# ATA5272 device description
Architecture: AVR8; Family: megaAVR
Registers are 8-bit, access not given, no defined reset value unless marked. A register's access mark holds for its fields unless they carry their own. Offsets are from the block's base; [hi:lo] are bit positions; {n}, {i} and the like mark numbered series; 'fields as' and 'values as' point back to an identical list.

## WDT — Watchdog Timer
Instances: WDT 0x00
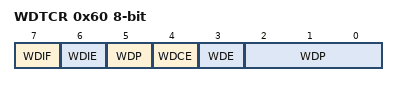
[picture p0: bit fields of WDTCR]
0x60 WDTCR — Watchdog Timer Control Register
  [7] WDIF — Watchdog Timeout Interrupt Flag
  [6] WDIE — Watchdog Timeout Interrupt Enable
  [4] WDCE — Watchdog Change Enable
  [3] WDE — Watch Dog Enable
  [5,2:0] WDP — Watchdog Timer Prescaler Bits
    0=Oscillator Cycles 2K; 1=Oscillator Cycles 4K; 2=Oscillator Cycles 8K; 3=Oscillator Cycles 16K; 4=Oscillator Cycles 32K; 5=Oscillator Cycles 64K; 6=Oscillator Cycles 128K; 7=Oscillator Cycles 256K; 8=Oscillator Cycles 512K; 9=Oscillator Cycles 1024K

## EEPROM
Instances: EEPROM 0x00
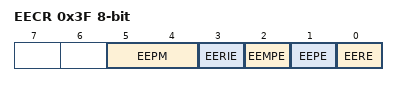
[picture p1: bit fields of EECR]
0x3F EECR — EEPROM Control Register
  [5:4] EEPM — EEPROM Programming Mode Bits
    0=Erase and Write in one operation; 1=Erase Only; 2=Write Only
  [3] EERIE — EEPROM Ready Interrupt Enable
  [2] EEMPE — EEPROM Master Write Enable
  [1] EEPE — EEPROM Write Enable
  [0] EERE — EEPROM Read Enable
0x40 EEDR — EEPROM Data Register
0x41 EEAR 16-bit bits used 8:0 — EEPROM Address Register Bytes

## SPI
Instances: SPI 0x00
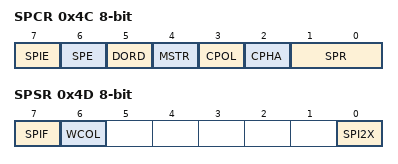
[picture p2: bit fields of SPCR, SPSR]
0x4C SPCR — SPI Control Register
  [7] SPIE — SPI Interrupt Enable
  [6] SPE — SPI Enable
  [5] DORD — Data Order
  [4] MSTR — Master/Slave Select
  [3] CPOL — Clock polarity
  [2] CPHA — Clock Phase
  [1:0] SPR — SPI Clock Rate Selects
    0=fosc/4; 1=fosc/16; 2=fosc/64; 3=fosc/128; 4=fosc/2; 5=fosc/8; 6=fosc/32; 7=fosc/64
0x4D SPSR — SPI Status Register
  [7] SPIF — SPI Interrupt Flag
  [6] WCOL — Write Collision Flag
  [0] SPI2X — Double SPI Speed Bit
0x4E SPDR — SPI Data Register

## AD_CONVERTER
Instances: AD_CONVERTER 0x00
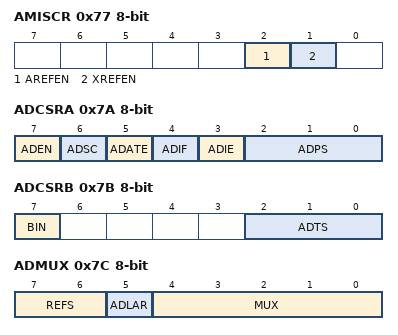
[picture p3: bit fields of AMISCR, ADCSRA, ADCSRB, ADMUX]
0x77 AMISCR — Analog Miscellaneous Control Register (Shared with CURRENT_SOURCE IO_MODULE)
  [2] AREFEN — External Voltage Reference Input Enable
  [1] XREFEN — Internal Voltage Reference Output Enable
0x78 ADC 16-bit — ADC Data Register Bytes
0x7A ADCSRA — The ADC Control and Status register A
  [7] ADEN — ADC Enable
  [6] ADSC — ADC Start Conversion
  [5] ADATE — ADC Auto Trigger Enable
  [4] ADIF — ADC Interrupt Flag
  [3] ADIE — ADC Interrupt Enable
  [2:0] ADPS — ADC Prescaler Select Bits
    0=2; 1=2; 2=4; 3=8; 4=16; 5=32; 6=64; 7=128
0x7B ADCSRB — The ADC Control and Status register B (Shared with ANALOG_COMPARATOR IO_MODULE)
  [7] BIN — Bipolar Input Mode
  [2:0] ADTS — ADC Auto Trigger Source bits
    0=Free Running mode; 1=Analog Comparator; 2=External Interrupt Request 0; 3=Timer/Counter1 Compare Match A; 4=Timer/Counter1 Overflow; 5=Timer/Counter1 Compare Match B; 6=Timer/Counter1 Capture Event; 7=Watchdog Interrupt Request
0x7C ADMUX — The ADC multiplexer Selection Register
  [7:6] REFS — Reference Selection Bits
    0=If AREFEN==0 then Internal AVCC as Voltage Reference. If AREFEN==1 then AREF pin as Voltage Reference.; 1=If AREFEN==0 then Internal 1.1V as Voltage Reference without external capacitor. If AREFEN==1 then Internal 1.1V as Voltage Reference with external capacitor at AREF pin.; 2=If AREFEN==0 then Internal AVCC as Voltage Reference. If AREFEN==1 then AREF pin as Voltage Reference.; 3=If AREFEN==0 then Internal 2.56V as Voltage Reference without external capacitor. If AREFEN==1 then Internal 2.56V as Voltage Reference with external capacitor at AREF pin.
  [5] ADLAR — Left Adjust Result
  [4:0] MUX — Analog Channel and Gain Selection Bits
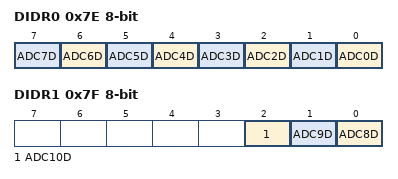
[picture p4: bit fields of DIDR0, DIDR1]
0x7E DIDR0 — Digital Input Disable Register 0
  [n] ADC{n}D (n=0..7)
0x7F DIDR1 — Digital Input Disable Register 1
  [2] ADC10D, [1] ADC9D, [0] ADC8D

## CURRENT_SOURCE
Instances: CURRENT_SOURCE 0x00
0x77 AMISCR — Analog Miscellaneous Control Register (Shared with AD_CONVERTER IO_MODULE)
  [0] ISRCEN — Current Source Enable

## ANALOG_COMPARATOR
Instances: ANALOG_COMPARATOR 0x00
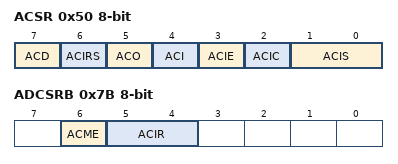
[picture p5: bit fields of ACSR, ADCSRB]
0x50 ACSR — Analog Comparator Control And Status Register
  [7] ACD — Analog Comparator Disable
  [6] ACIRS — Analog Comparator Internal Reference Select
  [5] ACO — Analog Compare Output
  [4] ACI — Analog Comparator Interrupt Flag
  [3] ACIE — Analog Comparator Interrupt Enable
  [2] ACIC — Analog Comparator Input Capture Enable
  [1:0] ACIS — Analog Comparator Interrupt Mode Select bits
    0=Interrupt on Toggle; 2=Interrupt on Falling Edge; 3=Interrupt on Rising Edge
0x7B ADCSRB — Analog Comparator & ADC Control and Status Register B (Shared with AD_CONVERTER IO_MODULE)
  [6] ACME — Analog Comparator Multiplexer Enable
  [5:4] ACIR — Analog Comparator Internal Voltage Reference Select Bits

## EXTERNAL_INTERRUPT
Instances: EXTERNAL_INTERRUPT 0x00
0x3B PCIFR — Pin Change Interrupt Flag Register
  [1:0] PCIF — Pin Change Interrupt Flags
0x3C EIFR — External Interrupt Flag Register
  [1:0] INTF — External Interrupt Flags
0x3D EIMSK — External Interrupt Mask Register
  [1:0] INT — External Interrupt Request 1 Enable
0x68 PCICR — Pin Change Interrupt Control Register
  [1:0] PCIE — Pin Change Interrupt Enable on any PCINT14..8 pin
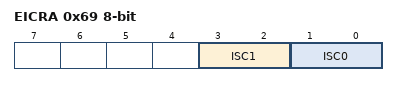
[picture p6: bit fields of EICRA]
0x69 EICRA — External Interrupt Control Register
  [3:2] ISC1 — External Interrupt Sense Control 1 Bits
    0=Low Level of INTX; 1=Any Logical Change in INTX; 2=Falling Edge of INTX; 3=Rising Edge of INTX
  [1:0] ISC0 — External Interrupt Sense Control 0 Bits
    values as ISC1
0x6B PCMSK0 — Pin Change Mask Register 0
  [7:0] PCINT — Pin Change Enable Masks
0x6C PCMSK1 — Pin Change Mask Register 1
  [7:0] PCINT (bit 8 of the value upward) — Pin Change Enable Masks

## BOOT_LOAD
Instances: BOOT_LOAD 0x00
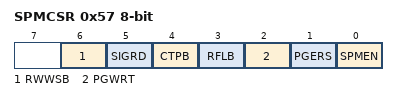
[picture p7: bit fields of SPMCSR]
0x57 SPMCSR — Store Program Memory Control Register
  [6] RWWSB — Read While Write Section Busy
  [5] SIGRD — Signature Row Read
  [4] CTPB — Clear Temporary Page Buffer
  [3] RFLB — Read Fuse and Lock Bits
  [2] PGWRT — Page Write
  [1] PGERS — Page Erase
  [0] SPMEN — Store Program Memory Enable

## CPU
Instances: CPU 0x00
Parameters: CORE_VERSION=V2, NEW_INSTRUCTIONS=lpm rd,z+
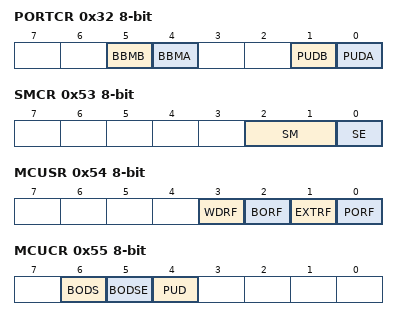
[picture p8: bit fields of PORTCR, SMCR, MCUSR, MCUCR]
0x32 PORTCR — Port Control Register
  [5] BBMB, [4] BBMA, [1] PUDB, [0] PUDA
0x3E GPIOR0 — General purpose register 0
0x4A GPIOR1 — General Purpose register 1
0x4B GPIOR2 — General Purpose IO register 2
0x51 DWDR — debugWire communication register
0x53 SMCR — Sleep Mode Control Register
  [2:1] SM — Sleep Mode Select Bits
    0=IDLE; 1=ADC (ADC Noise Reduction (If Available)); 2=PDOWN (Power Down); 3=PSAVE (Power Save)
  [0] SE — Sleep Enable
0x54 MCUSR — MCU Status register
  [3] WDRF — Watchdog Reset Flag
  [2] BORF — Brown-out Reset Flag
  [1] EXTRF — External Reset Flag
  [0] PORF — Power-On Reset Flag
0x55 MCUCR — MCU Control Register
  [6] BODS — BOD Sleep
  [5] BODSE — BOD Sleep Enable
  [4] PUD — Pull-up Disable
0x5D SP 16-bit bits used 10:0 — Stack Pointer Bytes
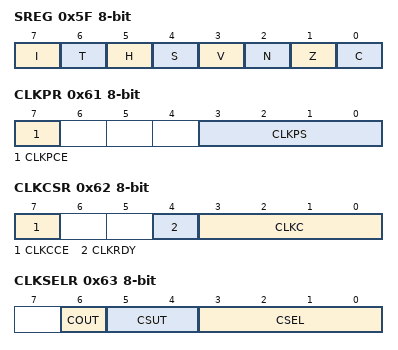
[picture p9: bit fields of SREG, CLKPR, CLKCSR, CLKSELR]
0x5F SREG — Status Register
  [7] I — Global Interrupt Enable
  [6] T — Bit Copy Storage
  [5] H — Half Carry Flag
  [4] S — Sign Bit
  [3] V — Two's Complement Overflow Flag
  [2] N — Negative Flag
  [1] Z — Zero Flag
  [0] C — Carry Flag
0x61 CLKPR — Clock Prescale Register
  [7] CLKPCE — Clock Prescaler Change Enable
  [3:0] CLKPS — Clock Prescaler Select Bits
    0=1; 1=2; 2=4; 3=8; 4=16; 5=32; 6=64; 7=128; 8=256
0x62 CLKCSR — Clock Control & Status Register
  [7] CLKCCE — Clock Control Change Enable
  [4] CLKRDY — Clock Ready Flag
  [3:0] CLKC — Clock Control bits
    0=No Command; 1=Disable Clock Source; 2=Enable Clock Source; 3=Request for Clock Availability; 4=Clock Source Switch; 5=Recovery System Clock Source Code; 6=Enable Watchdog in Automatic Reload Mode; 7=CKOUT Command; 8=From 0x08 up to 0x0F: No command
0x63 CLKSELR — Clock Selection Register
  [6] COUT — Clock Out - CKOUT fuse substitution
  [5:4] CSUT — Clock Start-up Time bit 1 - SUT1 fuse substitution
  [3:0] CSEL — Clock Source Select bit 3 - CKSEL3 fuse substitution
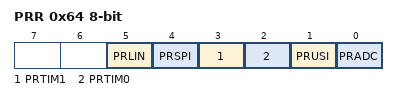
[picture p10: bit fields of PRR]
0x64 PRR — Power Reduction Register
  [5] PRLIN — Power Reduction LINUART
  [4] PRSPI — Power Reduction SPI
  [3] PRTIM1 — Power Reduction Timer/Counter1
  [2] PRTIM0 — Power Reduction Timer/Counter0
  [1] PRUSI — Power Reduction USI
  [0] PRADC — Power Reduction ADC
0x66 OSCCAL — Oscillator Calibration Register
  [7:0] OSCCAL — Oscillator Calibration
Value list OSCCAL_VALUE_ADDRESSES: 0=8_0_MHz
